NS_ :

BS_:

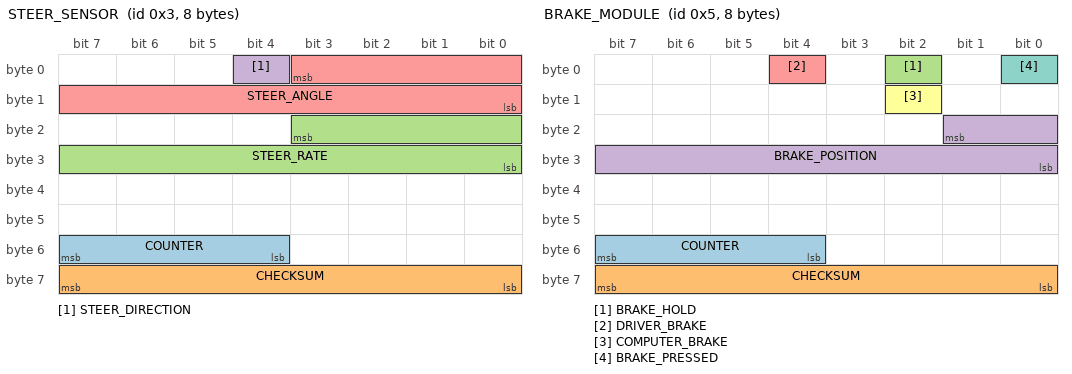
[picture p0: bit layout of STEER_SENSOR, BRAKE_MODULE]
BO_ 3 STEER_SENSOR: 8 XXX
 SG_ COUNTER : 55|4@0+ (1,0) [0|15] "" XXX
 SG_ CHECKSUM : 63|8@0+ (1,0) [0|255] "" XXX
 SG_ STEER_RATE : 19|12@0- (0.5,0) [0|255] "" XXX
 SG_ STEER_DIRECTION : 4|1@0+ (1,2) [0|1] "" XXX
 SG_ STEER_ANGLE : 3|12@0- (-0.5,0) [-500|500] "degrees" XXX

BO_ 5 BRAKE_MODULE: 8 XXX
 SG_ COUNTER : 55|4@0+ (1,0) [0|15] "" XXX
 SG_ CHECKSUM : 63|8@0+ (1,0) [0|255] "" XXX
 SG_ BRAKE_HOLD : 2|1@0+ (1,0) [0|1] "" XXX
 SG_ BRAKE_POSITION : 17|10@0+ (1,0) [0|65535] "" XXX
 SG_ DRIVER_BRAKE : 4|1@0+ (1,0) [0|1] "" XXX
 SG_ COMPUTER_BRAKE : 10|1@0+ (1,0) [0|1] "" XXX
 SG_ BRAKE_PRESSED : 0|1@1+ (1,0) [0|1] "" XXX

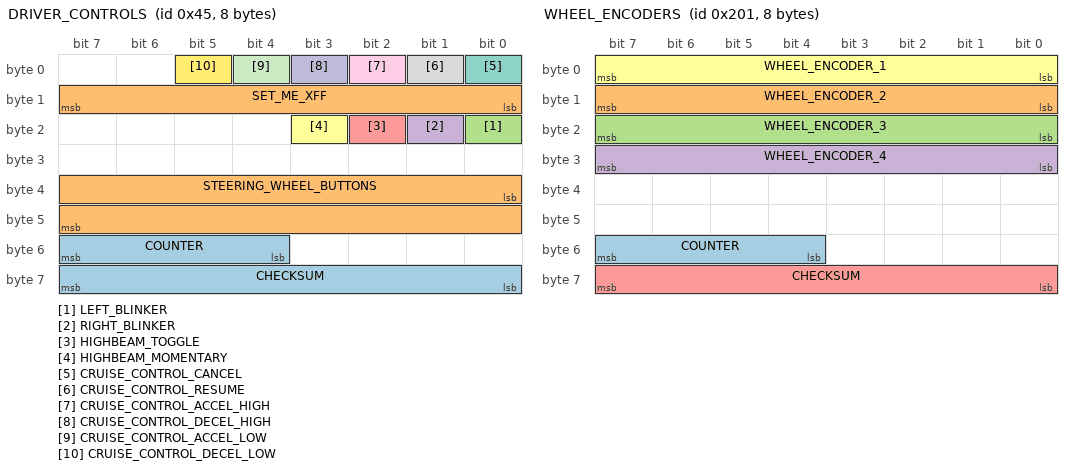
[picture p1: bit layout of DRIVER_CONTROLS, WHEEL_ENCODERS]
BO_ 69 DRIVER_CONTROLS: 8 XXX
 SG_ COUNTER : 55|4@0+ (1,0) [0|15] "" XXX
 SG_ STEERING_WHEEL_BUTTONS : 32|16@1+ (1,0) [0|255] "4 directional, 2 volume control & 2 phone buttons" XXX
 SG_ LEFT_BLINKER : 16|1@0+ (1,0) [0|1] "" XXX
 SG_ RIGHT_BLINKER : 17|1@0+ (1,0) [0|1] "" XXX
 SG_ HIGHBEAM_TOGGLE : 18|1@0+ (1,0) [0|1] "" XXX
 SG_ HIGHBEAM_MOMENTARY : 19|1@0+ (1,0) [0|1] "" XXX
 SG_ CRUISE_CONTROL_CANCEL : 0|1@0+ (1,0) [0|1] "" XXX
 SG_ CRUISE_CONTROL_RESUME : 1|1@0+ (1,0) [0|1] "" XXX
 SG_ CRUISE_CONTROL_ACCEL_HIGH : 2|1@0+ (1,0) [0|1] "" XXX
 SG_ CRUISE_CONTROL_DECEL_HIGH : 3|1@0+ (1,0) [0|1] "" XXX
 SG_ CRUISE_CONTROL_ACCEL_LOW : 4|1@0+ (1,0) [0|1] "" XXX
 SG_ CRUISE_CONTROL_DECEL_LOW : 5|1@0+ (1,0) [0|1] "" XXX
 SG_ CHECKSUM : 63|8@0+ (1,0) [0|255] "" XXX
 SG_ SET_ME_XFF : 15|8@0+ (1,0) [0|255] "" XXX

BO_ 513 WHEEL_ENCODERS: 8 XXX
 SG_ COUNTER : 55|4@0+ (1,0) [0|15] "" XXX
 SG_ WHEEL_ENCODER_2 : 15|8@0+ (1,0) [0|255] "" XXX
 SG_ WHEEL_ENCODER_3 : 23|8@0+ (1,0) [0|255] "" XXX
 SG_ WHEEL_ENCODER_4 : 31|8@0+ (1,0) [0|255] "" XXX
 SG_ CHECKSUM : 56|8@1+ (1,0) [0|255] "" XXX
 SG_ WHEEL_ENCODER_1 : 7|8@0+ (1,0) [0|255] "" XXX

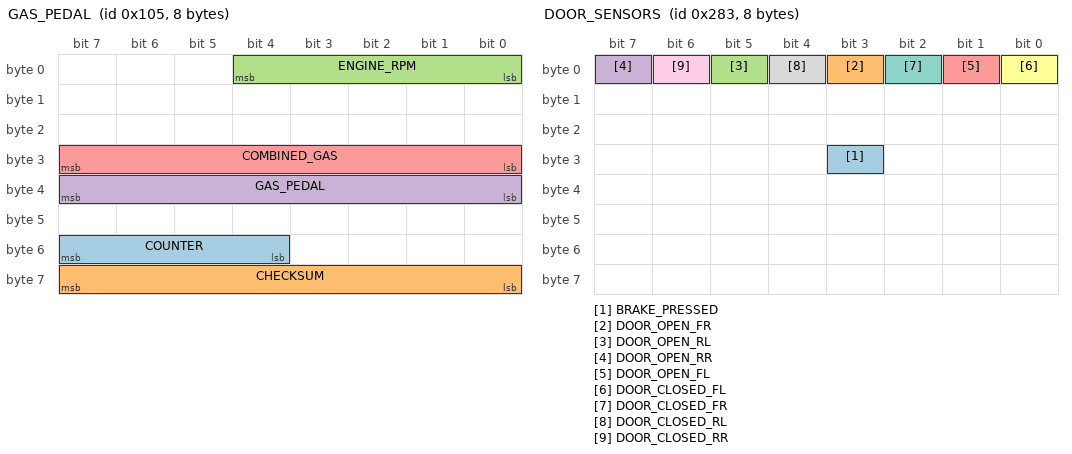
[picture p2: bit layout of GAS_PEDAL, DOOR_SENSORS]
BO_ 261 GAS_PEDAL: 8 XXX
 SG_ COUNTER : 55|4@0+ (1,0) [0|15] "" XXX
 SG_ CHECKSUM : 63|8@0+ (1,0) [0|255] "" XXX
 SG_ ENGINE_RPM : 4|5@0+ (1,0) [0|255] "" XXX
 SG_ GAS_PEDAL : 39|8@0+ (1,0) [0|255] "" XXX
 SG_ COMBINED_GAS : 31|8@0+ (1,0) [0|255] "" XXX

BO_ 643 DOOR_SENSORS: 8 XXX
 SG_ BRAKE_PRESSED : 27|1@0+ (1,0) [0|1] "" XXX
 SG_ DOOR_OPEN_FR : 3|1@1+ (1,0) [0|3] "" XXX
 SG_ DOOR_OPEN_RL : 5|1@0+ (1,0) [0|3] "" XXX
 SG_ DOOR_OPEN_RR : 7|1@0+ (1,0) [0|3] "" XXX
 SG_ DOOR_OPEN_FL : 1|1@0+ (1,0) [0|1] "" XXX
 SG_ DOOR_CLOSED_FL : 0|1@0+ (1,0) [0|1] "" XXX
 SG_ DOOR_CLOSED_FR : 2|1@0+ (1,0) [0|1] "" XXX
 SG_ DOOR_CLOSED_RL : 4|1@0+ (1,0) [0|1] "" XXX
 SG_ DOOR_CLOSED_RR : 6|1@0+ (1,0) [0|1] "" XXX

BO_ 885 SEATBELT_SENSORS: 8 XXX
 SG_ SEATBELT_DRIVER_LATCHED : 16|1@0+ (1,0) [0|1] "" XXX
 SG_ SEATBELT_PASSENGER_LATCHED : 18|1@0+ (1,0) [0|1] "" XXX

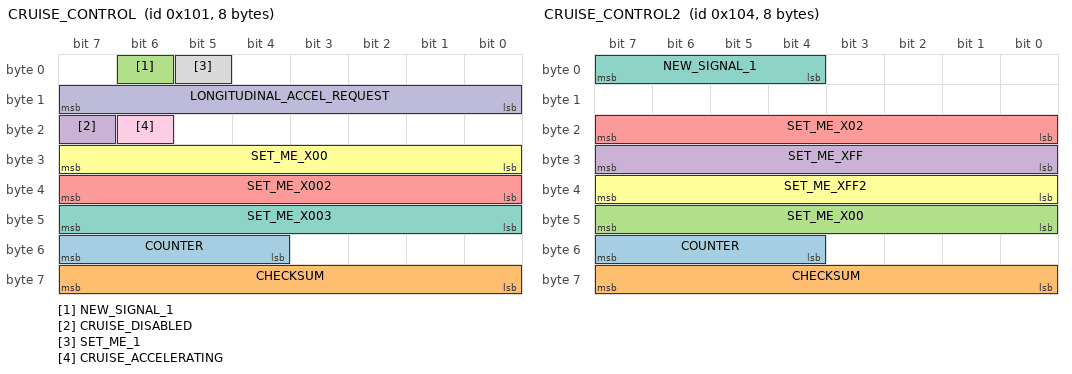
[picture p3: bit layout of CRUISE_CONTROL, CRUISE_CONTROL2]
BO_ 257 CRUISE_CONTROL: 8 XXX
 SG_ COUNTER : 55|4@0+ (1,0) [0|15] "" XXX
 SG_ CHECKSUM : 63|8@0+ (1,0) [0|255] "" XXX
 SG_ NEW_SIGNAL_1 : 6|1@0+ (1,0) [0|255] "" XXX
 SG_ CRUISE_DISABLED : 23|1@0+ (1,0) [0|1] "" XXX
 SG_ SET_ME_X002 : 39|8@0+ (1,0) [0|255] "" XXX
 SG_ SET_ME_X00 : 31|8@0+ (1,0) [0|255] "" XXX
 SG_ SET_ME_X003 : 47|8@0+ (1,0) [0|255] "" XXX
 SG_ SET_ME_1 : 5|1@0+ (1,0) [0|1] "" XXX
 SG_ CRUISE_ACCELERATING : 22|1@0+ (1,0) [0|1] "" XXX
 SG_ LONGITUDINAL_ACCEL_REQUEST : 15|8@0- (1,0) [0|127] "" XXX

BO_ 260 CRUISE_CONTROL2: 8 XXX
 SG_ COUNTER : 55|4@0+ (1,0) [0|15] "" XXX
 SG_ CHECKSUM : 63|8@0+ (1,0) [0|255] "" XXX
 SG_ SET_ME_X00 : 47|8@0+ (1,0) [0|255] "" XXX
 SG_ SET_ME_XFF : 31|8@0+ (1,0) [0|65535] "" XXX
 SG_ SET_ME_X02 : 23|8@0+ (1,0) [0|255] "" XXX
 SG_ SET_ME_XFF2 : 39|8@0+ (1,0) [0|255] "" XXX
 SG_ NEW_SIGNAL_1 : 7|4@0+ (1,0) [0|255] "" XXX

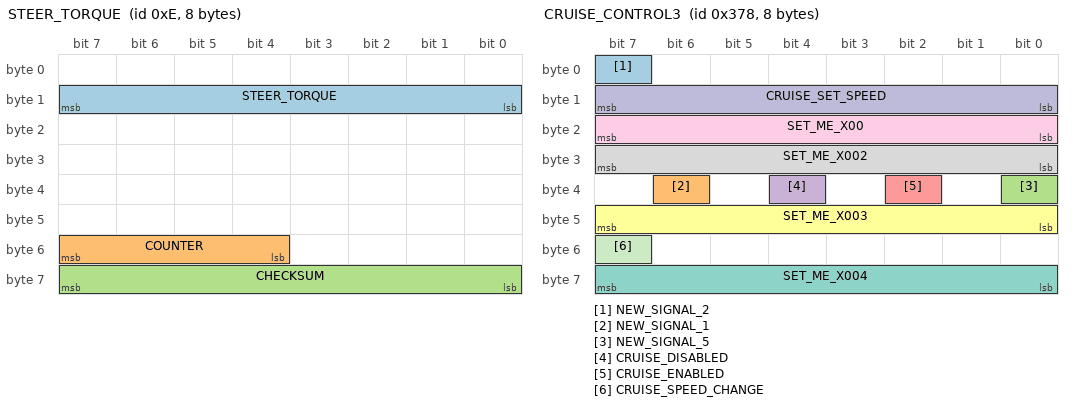
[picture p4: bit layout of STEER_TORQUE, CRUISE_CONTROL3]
BO_ 14 STEER_TORQUE: 8 XXX
 SG_ STEER_TORQUE : 15|8@0+ (1,0) [0|255] "" XXX
 SG_ COUNTER : 55|4@0+ (1,0) [0|15] "" XXX
 SG_ CHECKSUM : 63|8@0+ (1,0) [0|255] "" XXX

BO_ 888 CRUISE_CONTROL3: 8 XXX
 SG_ NEW_SIGNAL_2 : 7|1@0+ (1,0) [0|1] "" XXX
 SG_ NEW_SIGNAL_1 : 38|1@0+ (1,0) [0|1] "" XXX
 SG_ NEW_SIGNAL_5 : 32|1@0+ (1,0) [0|1] "" XXX
 SG_ CRUISE_DISABLED : 36|1@0+ (1,0) [0|1] "" XXX
 SG_ CRUISE_ENABLED : 34|1@0+ (1,0) [0|1] "" XXX
 SG_ SET_ME_X003 : 47|8@0+ (1,0) [0|255] "" XXX
 SG_ SET_ME_X004 : 63|8@0+ (1,0) [0|255] "" XXX
 SG_ SET_ME_X002 : 31|8@0+ (1,0) [0|255] "" XXX
 SG_ SET_ME_X00 : 23|8@0+ (1,0) [0|255] "" XXX
 SG_ CRUISE_SET_SPEED : 15|8@0+ (1,0) [0|63] "mph" XXX
 SG_ CRUISE_SPEED_CHANGE : 55|1@0+ (1,0) [0|1] "" XXX

BO_ 307 POWER_SEATS: 8 XXX
 SG_ DRIVER_FORWARD : 0|1@0+ (1,0) [0|1] "" XXX
 SG_ DRIVER_BACK : 1|1@0+ (1,0) [0|1] "" XXX

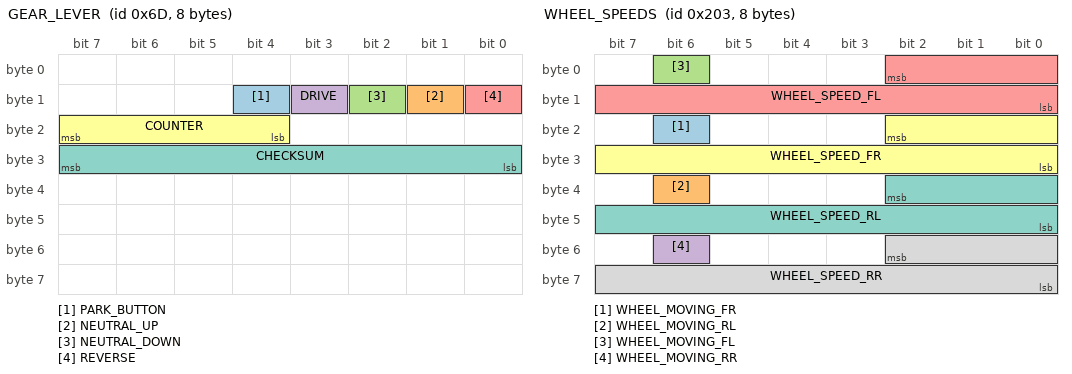
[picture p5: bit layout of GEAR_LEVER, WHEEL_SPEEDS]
BO_ 109 GEAR_LEVER: 8 XXX
 SG_ PARK_BUTTON : 12|1@0+ (1,0) [0|1] "" XXX
 SG_ NEUTRAL_UP : 9|1@0+ (1,0) [0|1] "" XXX
 SG_ NEUTRAL_DOWN : 10|1@0+ (1,0) [0|1] "" XXX
 SG_ DRIVE : 11|1@0+ (1,0) [0|1] "" XXX
 SG_ REVERSE : 8|1@0+ (1,0) [0|1] "" XXX
 SG_ COUNTER : 23|4@0+ (1,0) [0|15] "" XXX
 SG_ CHECKSUM : 31|8@0+ (1,0) [0|255] "" XXX

BO_ 115 GEAR_PACKET: 8 XXX
 SG_ GEAR : 0|4@1+ (1,0) [0|15] "" XXX

BO_ 581 IGNITION: 8 XXX

BO_ 515 WHEEL_SPEEDS: 8 XXX
 SG_ WHEEL_MOVING_FR : 22|1@1+ (1,0) [0|15] "" XXX
 SG_ WHEEL_MOVING_RL : 38|1@0+ (1,0) [0|1] "" XXX
 SG_ WHEEL_MOVING_FL : 6|1@0+ (1,0) [0|1] "" XXX
 SG_ WHEEL_MOVING_RR : 54|1@0+ (1,0) [0|1] "" XXX
 SG_ WHEEL_SPEED_FL : 2|11@0+ (0.0375,0) [0|255] "mph" XXX
 SG_ WHEEL_SPEED_FR : 18|11@0+ (0.0375,0) [0|255] "mph" XXX
 SG_ WHEEL_SPEED_RL : 34|11@0+ (0.0375,0) [0|255] "mph" XXX
 SG_ WHEEL_SPEED_RR : 50|11@0+ (0.0375,0) [0|255] "mph" XXX

BU_: GMLAN NEO
VAL_TABLE_ GearShifter 3 "Park" 0 "Drive/Low" ;
VAL_TABLE_ DriverDoorStatus 1 "Opened" 0 "Closed" ;
VAL_TABLE_ LKAGapButton 2 "???" 1 "??" 0 "None" ;
VAL_TABLE_ CruiseButtons 6 "Cancel" 5 "Main" 3 "Set" 2 "Resume" 1 "None" ;
VAL_TABLE_ CruiseControlActive 1 "Active" 0 "Inactive" ;
VAL_TABLE_ BlinkerStatus 1 "Active" 0 "Inactive" ;

CM_ "AUTOGENERATED FILE, DO NOT EDIT";

CM_ "Imported file _comma.dbc starts here";
CM_ "BO_ STEERING_IPAS_COMMA: Copy of msg 614 so we can do angle control while the Park Assist ECU is connected (Panda spoofs 614 with 359 on connector J70). Note that addresses 0x266 and 0x167 are checksum-invariant";

CM_ "BO_ SECONDARY_STEER_ANGLE: ZSS is a high-precision steering angle sensor that can replace the lower resolution sensor in most TSS1 Toyotas. Learn more: https://github.com/commaai/openpilot/wiki/Toyota-Lexus#zorro-steering-sensor-zss";

CM_ "BO_ SDSU: The sDSU is a modified DSU for use in TSS1 Toyotas. Learn more: https://github.com/wocsor/panda/tree/smart_dsu";
CM_ SG_ 767 FD_BUTTON "The follow distance button signal as forwarded by the sdsu";

CM_ "Imported file _toyota_2017.dbc starts here";
CM_ SG_ 36 YAW_RATE "verify";
CM_ SG_ 36 ACCEL_X "x-axis accel";
CM_ SG_ 37 STEER_FRACTION "1/15th of the signal STEER_ANGLE, which is 1.5 deg; note that 0x8 is never set";
CM_ SG_ 37 STEER_RATE "factor is tbd";
CM_ SG_ 466 NEUTRAL_FORCE "force in newtons the engine/electric motors are applying without any acceleration commands or user input";
CM_ SG_ 466 ACC_BRAKING "whether brakes are being actuated from ACC command";
CM_ SG_ 466 ACCEL_NET "net acceleration produced by the system, given ACCEL_CMD, road grade and other factors";
CM_ SG_ 466 CRUISE_STATE "Active state is 8, if standstill is requested will switch to state 11(3 sec timer), after timer is elapsed will switch into state 7(standstill). If plus button was pressed - status 9, minus button pressed - status 10";
CM_ SG_ 467 ACC_FAULTED "1 when ACC is faulted and the PCM disallows engagement";
CM_ SG_ 467 SET_SPEED "43 km/h are shown as 28 mph, so conversion isn't perfect";
CM_ SG_ 467 LOW_SPEED_LOCKOUT "in low speed lockout, system would always disengage below 28mph";
CM_ SG_ 560 BRAKE_PRESSED "another brake pressed?";
CM_ SG_ 581 GAS_PEDAL "it seems slightly filtered";
CM_ SG_ 608 STEER_TORQUE_DRIVER "driver torque";
CM_ SG_ 608 STEER_OVERRIDE "set when driver torque exceeds a certain value";
CM_ SG_ 614 ANGLE "set to measured angle when ipas control isn't active";
CM_ SG_ 643 _COUNTER "only used on cars that use this msg for cruise control";
CM_ SG_ 643 BRAKE_STATUS "only used on cars that use this msg for cruise control";
CM_ SG_ 643 PRECOLLISION_ACTIVE "set 0.5s before any braking";
CM_ SG_ 835 ACC_TYPE "if 2, car is likely to have a permanent low speed lockout. 1 is ok";
CM_ SG_ 835 RADAR_DIRTY "Display Clean Radar Sensor message on HUD";
CM_ SG_ 835 ACC_MALFUNCTION "display ACC fault on dash if set to 1";
CM_ SG_ 835 ACC_CUT_IN "Display blinking yellow lead if set to 1";
CM_ SG_ 835 DISTANCE "Cycle through ACC following distance from long, mid, short when set to 1";
CM_ SG_ 835 ITS_CONNECT_LEAD "Displayed when lead car is capable of ITS Connect";
CM_ SG_ 835 ALLOW_LONG_PRESS "Enable Toyota's factory set speed increment behaviour, available on both metrics cars and imperial unit cars";
CM_ SG_ 835 PERMIT_BRAKING "Original ACC has this going high when a car in front is detected. In openpilot and before the PERMIT_BRAKING name, this was 'SET_ME_1' and is hardcoded to be high. Unsure if only informational or has an effect though existing usage in openpilot is to always set it to 1. Originally 'PMTBRKG' in the leaked toyota_2017_ref_pt.dbc file and name expansion speculated to be PerMiT BRaKinG.";
CM_ SG_ 835 ACCEL_CMD_ALT "Copy of main ACCEL_CMD, but across 8 bits instead of 16 bits like ACCEL_CMD. Unsure if only informational or has an effect. Likely informational as existing openpilot sets this to 0 and no loss of functionality observed. Originally 'AT_RAW' in leaked toyota_2017_ref_pt.dbc file.";
CM_ SG_ 865 GAS_PEDAL_ALT "copy of main GAS_PEDAL. Both use 8 bits. Might indicate that this message is for pedals.";
CM_ SG_ 865 CLUTCH_RELEASED "boolean of clutch for 6MT.";
CM_ SG_ 865 ACC_FAULTED "1 when ACC is faulted and the PCM disallows engagement. Also describes a lockout when the ACC_CONTROL->ACC_MALFUNCTION bit is set.";
CM_ SG_ 921 UI_SET_SPEED "set speed shown in the vehicle's UI with the vehicle's unit";
CM_ SG_ 921 TEMP_ACC_FAULTED "1 when the UI is displaying or playing fault-related alerts or sounds. Also 1 when pressing main on.";
CM_ SG_ 951 BRAKE_LIGHTS_ACC "brake lights when ACC commands decel";
CM_ SG_ 956 GEAR "on 6MT, only R shows.";
CM_ SG_ 1009 UI_SET_SPEED "units seem to be whatever the car is set to";
CM_ SG_ 1041 PCS_INDICATOR "Pre-Collision System Indicator";
CM_ SG_ 1041 PCS_SENSITIVITY "Pre-Collision System Sensitivity";
CM_ SG_ 1041 PCS_DUST "alert: Front Camera Low Visibility Unavailable See Owner's Manual";
CM_ SG_ 1041 PCS_DUST2 "alert: Pre-Collision System Radar Sensor Blocked Unavailable Clean Radar Sensor";
CM_ SG_ 1041 PCS_TEMP "alert: Front Camera Out of Temperature Range Unavailable Wait until Normal Temperature";
CM_ SG_ 1041 PCS_TEMP2 "alert: Pre-Collision System Out of Temperature Range Unavailable See Owner's Manual";
CM_ SG_ 1041 FRD_ADJ "alert: ERROR ADJUSTING FRONT RADAR BEAM";
CM_ SG_ 1042 LDA_SA_TOGGLE "LDA Steering Assist Toggle";
CM_ SG_ 1042 LDW_EXIST "Unclear what this is, it's usually set to 0";
CM_ SG_ 1042 LDA_SENSITIVITY "LDA Sensitivity";
CM_ SG_ 1042 LDA_ON_MESSAGE "Display LDA Turned ON message";
CM_ SG_ 1042 REPEATED_BEEPS "LDA audible warning";
CM_ SG_ 1042 LDA_UNAVAILABLE_QUIET "LDA toggles and sensitivity settings are greyed out if set to 1";
CM_ SG_ 1042 LDA_MESSAGES "Various LDA Messages";
CM_ SG_ 1042 LDA_FRONT_CAMERA_BLOCKED "originally LDAFCVB, LDA related settings are greyed out if set to 1";
CM_ SG_ 1042 TAKE_CONTROL "Please Control Steering Wheel warning";
CM_ SG_ 1042 LANE_SWAY_TOGGLE "Lane Sway Warning System SWS Switch";
CM_ SG_ 1042 LANE_SWAY_WARNING "Lane Sway Warning System Triggered";
CM_ SG_ 1042 LANE_SWAY_FLD "Unknown signal for Lane Sway Warning System, set to 7 on stock system when SWS is enabled, 0 when SWS is disabled";
CM_ SG_ 1042 LANE_SWAY_BUZZER "Similar to TWO_BEEPS";
CM_ SG_ 1042 SET_ME_X01 "empty bit on leaked dbc, always set to 1 during normal operations";
CM_ SG_ 1042 SET_ME_X02 "empty bit on leaked dbc, always set to 2 during normal operations";
CM_ SG_ 1083 STATE "when the dashboard button is pressed, the value changes from zero to non-zero";
CM_ SG_ 1161 SPDVAL1 "Numbers 0-199 is displayed, 200-254 displays circle without number and 255 is for no limit.";
CM_ SG_ 1161 SYNCID1 "counter from 1 to f at 1 Hz";
CM_ SG_ 1161 SPDVAL2 "conditional speed value 70";
CM_ SG_ 1162 SGNNUMP "1 if SPDVAL1 is set, otherwise 0";
CM_ SG_ 1162 SYNCID2 "counter from 1 to f at 1 Hz";
CM_ SG_ 1163 TSREQPD "always 1";
CM_ SG_ 1163 TSRMSW "always 1";
CM_ SG_ 1163 OTSGNNTM "always 3";
CM_ SG_ 1163 NTLVLSPD "always 3";
CM_ SG_ 1163 OVSPNTM "always 3";
CM_ SG_ 1163 OVSPVALL "-5 at start then 2 after 2 seconds";
CM_ SG_ 1163 OVSPVALM "-5 at start then 5 after 2 seconds";
CM_ SG_ 1163 OVSPVALH "-5 at start then 10 after 2 seconds";
CM_ SG_ 1163 TSRSPU "always 1";
CM_ SG_ 1552 UI_SPEED "Does not appear to match dash";
CM_ SG_ 1552 METER_SLIDER_BRIGHTNESS_PCT "Combination display brightness setting, scales from 12 per cent to 100 per cent, reflects combination meter settings only, not linked with headlight state";
CM_ SG_ 1552 METER_SLIDER_LOW_BRIGHTNESS "Combination display low brightness mode, also controls footwell lighting";
CM_ SG_ 1552 METER_SLIDER_DIMMED "Combination display slider not at max, reflects combination meter settings only, not linked with headlight state";
CM_ SG_ 1553 ODOMETER "Unit is dependent upon units signal";
CM_ SG_ 1592 LOCK_STATUS_CHANGED "1 on rising edge of lock/unlocking";
CM_ SG_ 1592 LOCK_STATUS "The next 3 bits always seem to follow this signal.";
CM_ SG_ 1592 LOCKED_VIA_KEYFOB "1 for as long as car is locked with key fob or door handle touch";

CM_ "toyota_new_mc_pt.dbc starts here";

CM_ SG_ 548 BRAKE_PRESSURE "seems prop to pedal force";
CM_ SG_ 548 BRAKE_POSITION "seems proportional to pedal displacement, unclear the max value of 0x1c8";
CM_ SG_ 610 TYPE "seems 1 on Corolla, 0 on all others";
